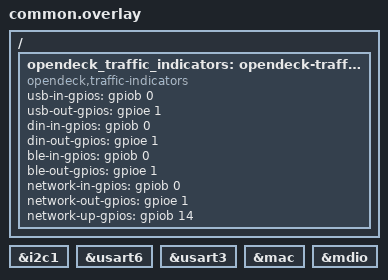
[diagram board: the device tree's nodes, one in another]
opendeck_i2c_bus: &i2c1 {};

opendeck_uart_din_midi: &usart6 {};

opendeck_uart_touchscreen: &usart6 {};

&usart3 {
    status = "okay";
};

&mac {
    status = "okay";
};

&mdio {
    status = "okay";
};

/ {
    opendeck_traffic_indicators: opendeck-traffic-indicators {
        compatible = "opendeck,traffic-indicators";
        usb-in-gpios = <&gpiob 0 GPIO_ACTIVE_HIGH>;
        usb-out-gpios = <&gpioe 1 GPIO_ACTIVE_HIGH>;
        din-in-gpios = <&gpiob 0 GPIO_ACTIVE_HIGH>;
        din-out-gpios = <&gpioe 1 GPIO_ACTIVE_HIGH>;
        ble-in-gpios = <&gpiob 0 GPIO_ACTIVE_HIGH>;
        ble-out-gpios = <&gpioe 1 GPIO_ACTIVE_HIGH>;
        network-in-gpios = <&gpiob 0 GPIO_ACTIVE_HIGH>;
        network-out-gpios = <&gpioe 1 GPIO_ACTIVE_HIGH>;
        network-up-gpios = <&gpiob 14 GPIO_ACTIVE_HIGH>;
    };
};
